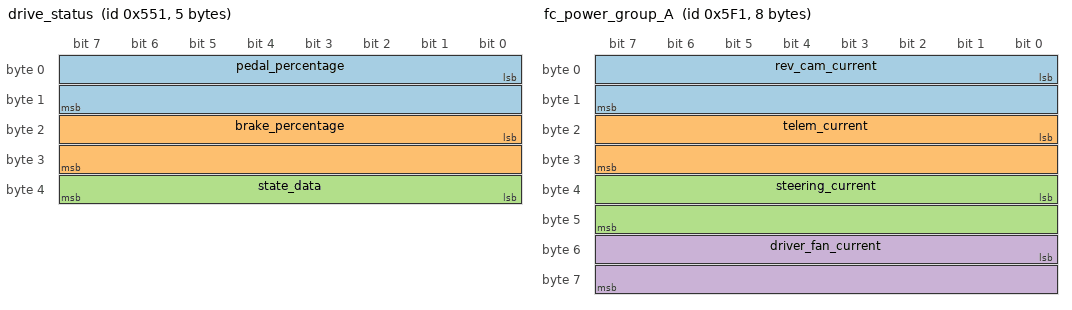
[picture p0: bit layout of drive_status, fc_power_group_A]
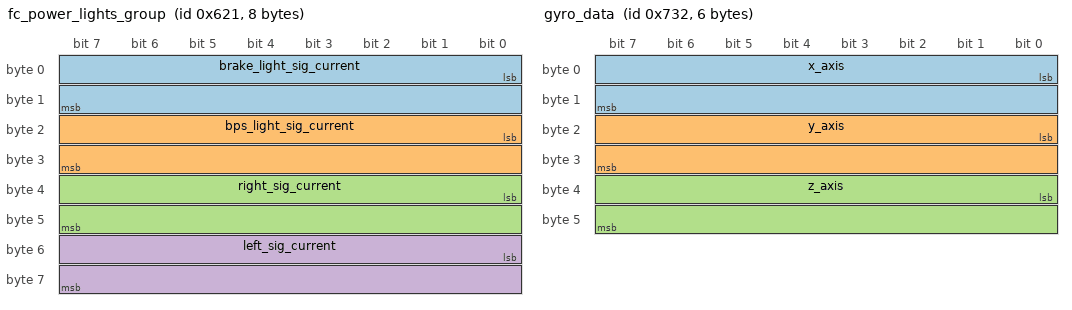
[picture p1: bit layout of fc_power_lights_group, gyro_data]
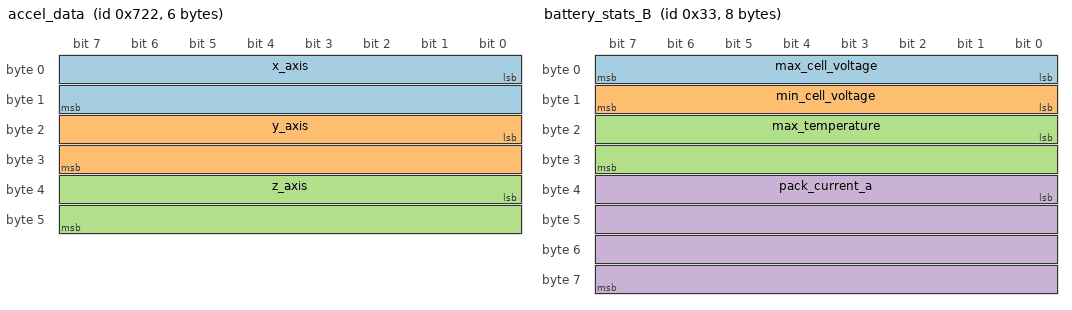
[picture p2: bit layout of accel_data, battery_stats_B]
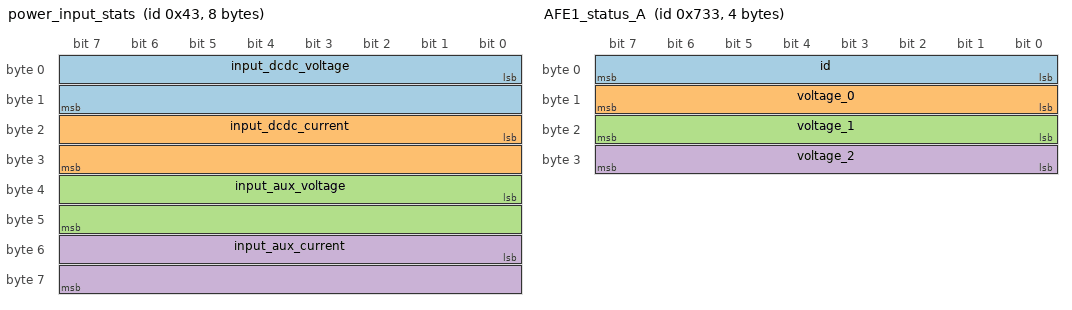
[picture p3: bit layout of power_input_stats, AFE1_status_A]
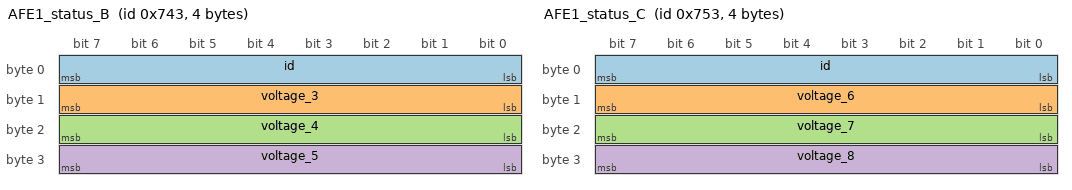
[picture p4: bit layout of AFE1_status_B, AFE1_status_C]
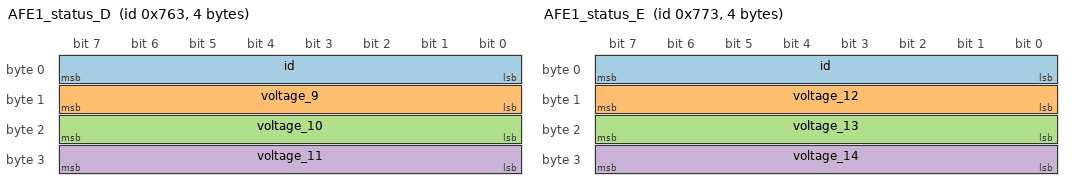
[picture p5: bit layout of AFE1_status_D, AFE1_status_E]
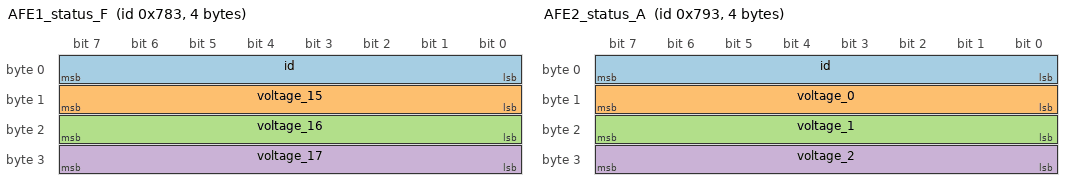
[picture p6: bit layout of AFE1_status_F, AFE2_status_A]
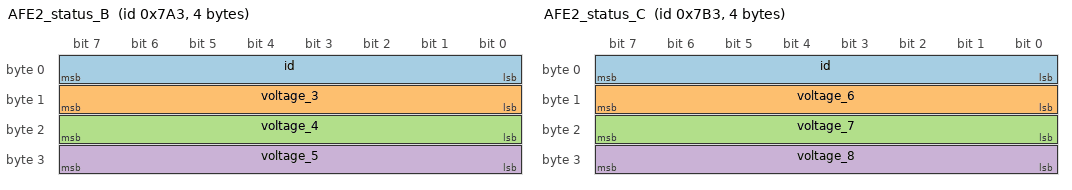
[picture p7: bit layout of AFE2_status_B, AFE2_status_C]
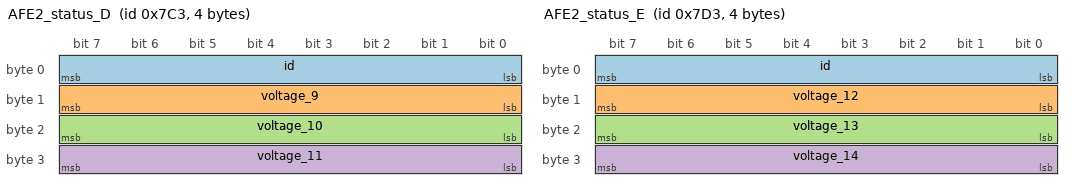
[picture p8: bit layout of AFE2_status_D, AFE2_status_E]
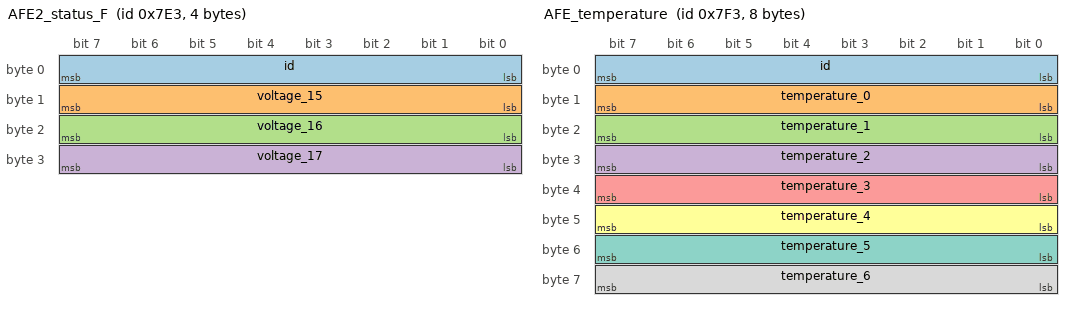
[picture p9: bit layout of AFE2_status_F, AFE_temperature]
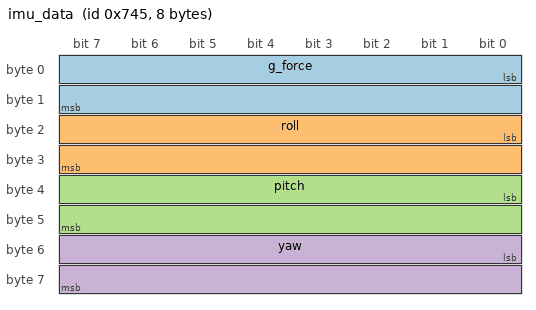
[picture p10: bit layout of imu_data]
NS_ :

BS_:

BU_: CAN_COMMUNICATION FRONT_CONTROLLER IMU REAR_CONTROLLER STEERING TELEMETRY

BO_   1904 fast_one_shot_msg: 4 can_communication
  SG_ sig1 : 0|16@1+ (1,0) [0|65535] "" can_communication
  SG_ sig2 : 16|16@1+ (1,0) [0|65535] "" can_communication

BO_   1888 medium_one_shot_msg: 4 can_communication
  SG_ sig1 : 0|16@1+ (1,0) [0|65535] "" can_communication
  SG_ sig2 : 16|16@1+ (1,0) [0|65535] "" can_communication

BO_   1872 slow_one_shot_msg: 4 can_communication
  SG_ sig1 : 0|16@1+ (1,0) [0|65535] "" can_communication
  SG_ sig2 : 16|16@1+ (1,0) [0|65535] "" can_communication

BO_   1361 drive_status: 5 front_controller
  SG_ pedal_percentage : 0|16@1+ (1,0) [0|65535] "" telemetry, steering, rear_controller
  SG_ brake_percentage : 16|16@1+ (1,0) [0|65535] "" telemetry, steering, rear_controller
  SG_ state_data : 32|8@1+ (1,0) [|] "" telemetry, steering, rear_controller

BO_   1521 fc_power_group_A: 8 front_controller
  SG_ rev_cam_current : 0|16@1+ (1,0) [0|65535] "" telemetry
  SG_ telem_current : 16|16@1+ (1,0) [0|65535] "" telemetry
  SG_ steering_current : 32|16@1+ (1,0) [0|65535] "" telemetry
  SG_ driver_fan_current : 48|16@1+ (1,0) [0|65535] "" telemetry

BO_   1617 fc_power_group_B: 4 front_controller
  SG_ horn_current : 0|16@1+ (1,0) [0|65535] "" telemetry
  SG_ spare_current : 16|16@1+ (1,0) [0|65535] "" telemetry

BO_   1569 fc_power_lights_group: 8 front_controller
  SG_ brake_light_sig_current : 0|16@1+ (1,0) [0|65535] "" telemetry
  SG_ bps_light_sig_current : 16|16@1+ (1,0) [0|65535] "" telemetry
  SG_ right_sig_current : 32|16@1+ (1,0) [0|65535] "" telemetry
  SG_ left_sig_current : 48|16@1+ (1,0) [0|65535] "" telemetry

BO_   1745 pedal_calib_status: 1 front_controller
  SG_ status : 0|8@1+ (1,0) [0|255] "" steering

BO_   1842 gyro_data: 6 imu
  SG_ x_axis : 0|16@1+ (1,0) [0|65535] "" telemetry
  SG_ y_axis : 16|16@1+ (1,0) [0|65535] "" telemetry
  SG_ z_axis : 32|16@1+ (1,0) [0|65535] "" telemetry

BO_   1826 accel_data: 6 imu
  SG_ x_axis : 0|16@1+ (1,0) [0|65535] "" telemetry
  SG_ y_axis : 16|16@1+ (1,0) [0|65535] "" telemetry
  SG_ z_axis : 32|16@1+ (1,0) [0|65535] "" telemetry

BO_  19  rear_controller_status: 4 rear_controller
  SG_ triggers : 0|32@1+ (1,0) [|] "" telemetry, front_controller, steering

BO_  35  battery_stats_A: 6 rear_controller
  SG_ pack_voltage_v : 0|32@1+ (1,0) [0.0|200.0] "" telemetry, front_controller, steering
  SG_ pack_soc : 32|16@1+ (1,0) [0.0|100.0] "" telemetry, front_controller, steering

BO_  51  battery_stats_B: 8 rear_controller
  SG_ max_cell_voltage : 0|8@1+ (1,0) [20000.0|50000.0] "" telemetry, front_controller, steering
  SG_ min_cell_voltage : 8|8@1+ (1,0) [20000.0|50000.0] "" telemetry, front_controller, steering
  SG_ max_temperature : 16|16@1+ (1,0) [0|65535] "" telemetry, front_controller, steering
  SG_ pack_current_a : 32|32@1+ (1,0) [-200.0|200.0] "" telemetry, front_controller, steering

BO_   1107 bps_fault_info: 8 rear_controller
  SG_ extra_info : 0|64@1+ (1,0) [0|18446744073709551615] "" telemetry, steering

BO_  67  power_input_stats: 8 rear_controller
  SG_ input_dcdc_voltage : 0|16@1+ (1,0) [0|65535] "" telemetry, steering
  SG_ input_dcdc_current : 16|16@1+ (1,0) [0|65535] "" telemetry, steering
  SG_ input_aux_voltage : 32|16@1+ (1,0) [0|65535] "" telemetry, steering
  SG_ input_aux_current : 48|16@1+ (1,0) [0|65535] "" telemetry, steering

BO_   1827 AFE_discharge_bitset: 8 rear_controller
  SG_ AFE1 : 0|32@1+ (1,0) [|] "" telemetry, steering
  SG_ AFE2 : 32|32@1+ (1,0) [|] "" telemetry, steering

BO_   1843 AFE1_status_A: 4 rear_controller
  SG_ id : 0|8@1+ (1,0) [0|255] "" telemetry, steering
  SG_ voltage_0 : 8|8@1+ (1,0) [20000.0|50000.0] "" telemetry, steering
  SG_ voltage_1 : 16|8@1+ (1,0) [20000.0|50000.0] "" telemetry, steering
  SG_ voltage_2 : 24|8@1+ (1,0) [20000.0|50000.0] "" telemetry, steering

BO_   1859 AFE1_status_B: 4 rear_controller
  SG_ id : 0|8@1+ (1,0) [0|255] "" telemetry, steering
  SG_ voltage_3 : 8|8@1+ (1,0) [20000.0|50000.0] "" telemetry, steering
  SG_ voltage_4 : 16|8@1+ (1,0) [20000.0|50000.0] "" telemetry, steering
  SG_ voltage_5 : 24|8@1+ (1,0) [20000.0|50000.0] "" telemetry, steering

BO_   1875 AFE1_status_C: 4 rear_controller
  SG_ id : 0|8@1+ (1,0) [0|255] "" telemetry, steering
  SG_ voltage_6 : 8|8@1+ (1,0) [20000.0|50000.0] "" telemetry, steering
  SG_ voltage_7 : 16|8@1+ (1,0) [20000.0|50000.0] "" telemetry, steering
  SG_ voltage_8 : 24|8@1+ (1,0) [20000.0|50000.0] "" telemetry, steering

BO_   1891 AFE1_status_D: 4 rear_controller
  SG_ id : 0|8@1+ (1,0) [0|255] "" telemetry, steering
  SG_ voltage_9 : 8|8@1+ (1,0) [20000.0|50000.0] "" telemetry, steering
  SG_ voltage_10 : 16|8@1+ (1,0) [20000.0|50000.0] "" telemetry, steering
  SG_ voltage_11 : 24|8@1+ (1,0) [20000.0|50000.0] "" telemetry, steering

BO_   1907 AFE1_status_E: 4 rear_controller
  SG_ id : 0|8@1+ (1,0) [0|255] "" telemetry, steering
  SG_ voltage_12 : 8|8@1+ (1,0) [20000.0|50000.0] "" telemetry, steering
  SG_ voltage_13 : 16|8@1+ (1,0) [20000.0|50000.0] "" telemetry, steering
  SG_ voltage_14 : 24|8@1+ (1,0) [20000.0|50000.0] "" telemetry, steering

BO_   1923 AFE1_status_F: 4 rear_controller
  SG_ id : 0|8@1+ (1,0) [0|255] "" telemetry, steering
  SG_ voltage_15 : 8|8@1+ (1,0) [20000.0|50000.0] "" telemetry, steering
  SG_ voltage_16 : 16|8@1+ (1,0) [20000.0|50000.0] "" telemetry, steering
  SG_ voltage_17 : 24|8@1+ (1,0) [20000.0|50000.0] "" telemetry, steering

BO_   1939 AFE2_status_A: 4 rear_controller
  SG_ id : 0|8@1+ (1,0) [0|255] "" telemetry, steering
  SG_ voltage_0 : 8|8@1+ (1,0) [20000.0|50000.0] "" telemetry, steering
  SG_ voltage_1 : 16|8@1+ (1,0) [20000.0|50000.0] "" telemetry, steering
  SG_ voltage_2 : 24|8@1+ (1,0) [20000.0|50000.0] "" telemetry, steering

BO_   1955 AFE2_status_B: 4 rear_controller
  SG_ id : 0|8@1+ (1,0) [0|255] "" telemetry, steering
  SG_ voltage_3 : 8|8@1+ (1,0) [20000.0|50000.0] "" telemetry, steering
  SG_ voltage_4 : 16|8@1+ (1,0) [20000.0|50000.0] "" telemetry, steering
  SG_ voltage_5 : 24|8@1+ (1,0) [20000.0|50000.0] "" telemetry, steering

BO_   1971 AFE2_status_C: 4 rear_controller
  SG_ id : 0|8@1+ (1,0) [0|255] "" telemetry, steering
  SG_ voltage_6 : 8|8@1+ (1,0) [20000.0|50000.0] "" telemetry, steering
  SG_ voltage_7 : 16|8@1+ (1,0) [20000.0|50000.0] "" telemetry, steering
  SG_ voltage_8 : 24|8@1+ (1,0) [20000.0|50000.0] "" telemetry, steering

BO_   1987 AFE2_status_D: 4 rear_controller
  SG_ id : 0|8@1+ (1,0) [0|255] "" telemetry, steering
  SG_ voltage_9 : 8|8@1+ (1,0) [20000.0|50000.0] "" telemetry, steering
  SG_ voltage_10 : 16|8@1+ (1,0) [20000.0|50000.0] "" telemetry, steering
  SG_ voltage_11 : 24|8@1+ (1,0) [20000.0|50000.0] "" telemetry, steering

BO_   2003 AFE2_status_E: 4 rear_controller
  SG_ id : 0|8@1+ (1,0) [0|255] "" telemetry, steering
  SG_ voltage_12 : 8|8@1+ (1,0) [20000.0|50000.0] "" telemetry, steering
  SG_ voltage_13 : 16|8@1+ (1,0) [20000.0|50000.0] "" telemetry, steering
  SG_ voltage_14 : 24|8@1+ (1,0) [20000.0|50000.0] "" telemetry, steering

BO_   2019 AFE2_status_F: 4 rear_controller
  SG_ id : 0|8@1+ (1,0) [0|255] "" telemetry, steering
  SG_ voltage_15 : 8|8@1+ (1,0) [20000.0|50000.0] "" telemetry, steering
  SG_ voltage_16 : 16|8@1+ (1,0) [20000.0|50000.0] "" telemetry, steering
  SG_ voltage_17 : 24|8@1+ (1,0) [20000.0|50000.0] "" telemetry, steering

BO_   2035 AFE_temperature: 8 rear_controller
  SG_ id : 0|8@1+ (1,0) [0|255] "" telemetry, steering
  SG_ temperature_0 : 8|8@1+ (1,0) [0|255] "" telemetry, steering
  SG_ temperature_1 : 16|8@1+ (1,0) [0|255] "" telemetry, steering
  SG_ temperature_2 : 24|8@1+ (1,0) [0|255] "" telemetry, steering
  SG_ temperature_3 : 32|8@1+ (1,0) [0|255] "" telemetry, steering
  SG_ temperature_4 : 40|8@1+ (1,0) [0|255] "" telemetry, steering
  SG_ temperature_5 : 48|8@1+ (1,0) [0|255] "" telemetry, steering
  SG_ temperature_6 : 56|8@1+ (1,0) [0|255] "" telemetry, steering

BO_  100  steering: 6 steering
  SG_ cruise_control_target_velocity : 0|32@1+ (1,0) [0|4294967295] "" telemetry, front_controller, rear_controller
  SG_ buttons : 32|16@1+ (1,0) [|] "" telemetry, front_controller, rear_controller

BO_   1764 pedal_calib_request: 1 steering
  SG_ command : 0|8@1+ (1,0) [0|255] "" front_controller

BO_   1861 imu_data: 8 telemetry
  SG_ g_force : 0|16@1+ (1,0) [0|65535] "" steering
  SG_ roll : 16|16@1+ (1,0) [0|65535] "" steering
  SG_ pitch : 32|16@1+ (1,0) [0|65535] "" steering
  SG_ yaw : 48|16@1+ (1,0) [0|65535] "" steering
